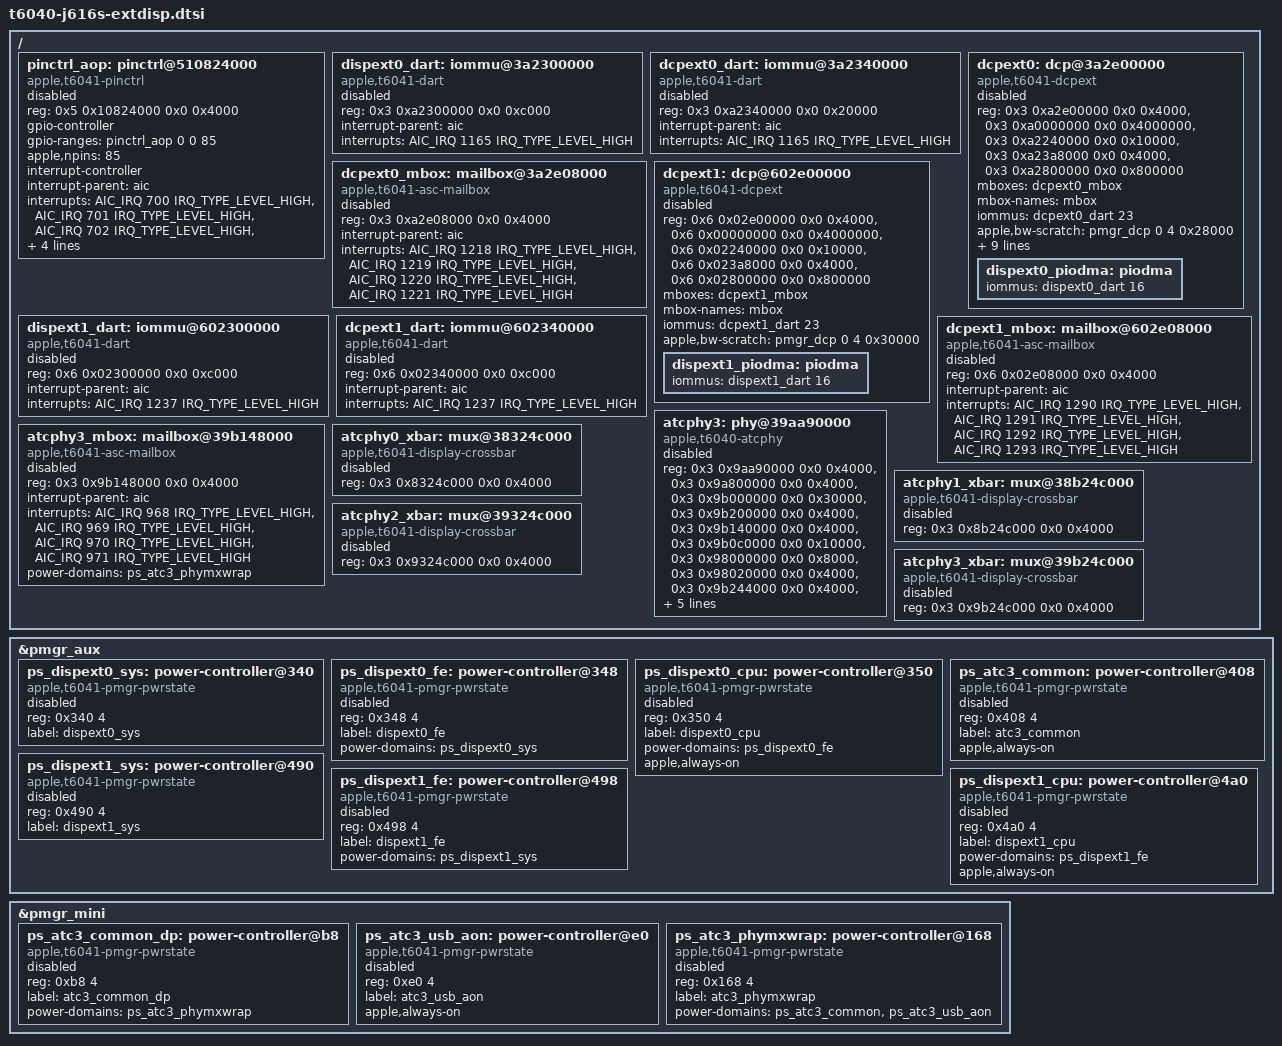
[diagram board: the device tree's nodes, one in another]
// SPDX-License-Identifier: GPL-2.0+ OR MIT
/*
 * External display resources of the J616s (T6041): HDMI and USB-C. Every
 * node is left disabled, so the booted hardware state is unchanged until
 * the kernel display gate (or a loader) enables the chain in order.
 *
 * Values come from this unit's ADT (macOS 25G83, this one unit); CPU
 * address = ADT address + 0x2_0000_0000. Path of the picture:
 *   HDMI:  dcpext0 -> atc3 display crossbar -> atcphy3 (fixed DP PHY, no
 *          USB controller) -> on-board DP-to-HDMI converter
 *   USB-C: dcpext1 -> atcN display crossbar -> atcphyN (DP alt mode)
 */

/ {
	pinctrl_aop: pinctrl@510824000 {
		compatible = "apple,t6041-pinctrl", "apple,t8103-pinctrl";
		reg = <0x5 0x10824000 0x0 0x4000>;

		gpio-controller;
		#gpio-cells = <2>;
		gpio-ranges = <&pinctrl_aop 0 0 85>;
		apple,npins = <85>;

		interrupt-controller;
		#interrupt-cells = <2>;
		interrupt-parent = <&aic>;
		interrupts = <AIC_IRQ 700 IRQ_TYPE_LEVEL_HIGH>,
			     <AIC_IRQ 701 IRQ_TYPE_LEVEL_HIGH>,
			     <AIC_IRQ 702 IRQ_TYPE_LEVEL_HIGH>,
			     <AIC_IRQ 703 IRQ_TYPE_LEVEL_HIGH>,
			     <AIC_IRQ 704 IRQ_TYPE_LEVEL_HIGH>,
			     <AIC_IRQ 705 IRQ_TYPE_LEVEL_HIGH>,
			     <AIC_IRQ 706 IRQ_TYPE_LEVEL_HIGH>;
		status = "disabled";
	};

	dispext0_dart: iommu@3a2300000 {
		compatible = "apple,t6041-dart", "apple,t8110-dart";
		reg = <0x3 0xa2300000 0x0 0xc000>;
		#iommu-cells = <1>;
		interrupt-parent = <&aic>;
		interrupts = <AIC_IRQ 1165 IRQ_TYPE_LEVEL_HIGH>;
		status = "disabled";
	};

	dcpext0_dart: iommu@3a2340000 {
		compatible = "apple,t6041-dart", "apple,t8110-dart";
		reg = <0x3 0xa2340000 0x0 0x20000>;
		#iommu-cells = <1>;
		interrupt-parent = <&aic>;
		interrupts = <AIC_IRQ 1165 IRQ_TYPE_LEVEL_HIGH>;
		status = "disabled";
	};

	dcpext0: dcp@3a2e00000 {
		compatible = "apple,t6041-dcpext", "apple,dcpext";
		reg = <0x3 0xa2e00000 0x0 0x4000>,
		      <0x3 0xa0000000 0x0 0x4000000>,
		      <0x3 0xa2240000 0x0 0x10000>,
		      <0x3 0xa23a8000 0x0 0x4000>,
		      <0x3 0xa2800000 0x0 0x800000>;
		reg-names = "coproc", "disp-0", "disp-1", "disp-2", "disp-3";
		mboxes = <&dcpext0_mbox>;
		mbox-names = "mbox";
		iommus = <&dcpext0_dart 23>;
		/* guessed: the internal DCP uses 0x20000, J700 DISPEXT0 is +0x8000 */
		apple,bw-scratch = <&pmgr_dcp 0 4 0x28000>;
		status = "disabled";

		dispext0_piodma: piodma {
			iommus = <&dispext0_dart 16>;
		};
	};

	dcpext0_mbox: mailbox@3a2e08000 {
		compatible = "apple,t6041-asc-mailbox", "apple,asc-mailbox-v4";
		reg = <0x3 0xa2e08000 0x0 0x4000>;
		interrupt-parent = <&aic>;
		interrupts = <AIC_IRQ 1218 IRQ_TYPE_LEVEL_HIGH>,
			     <AIC_IRQ 1219 IRQ_TYPE_LEVEL_HIGH>,
			     <AIC_IRQ 1220 IRQ_TYPE_LEVEL_HIGH>,
			     <AIC_IRQ 1221 IRQ_TYPE_LEVEL_HIGH>;
		interrupt-names = "send-empty", "send-not-empty",
				  "recv-empty", "recv-not-empty";
		#mbox-cells = <0>;
		status = "disabled";
	};

	dispext1_dart: iommu@602300000 {
		compatible = "apple,t6041-dart", "apple,t8110-dart";
		reg = <0x6 0x02300000 0x0 0xc000>;
		#iommu-cells = <1>;
		interrupt-parent = <&aic>;
		interrupts = <AIC_IRQ 1237 IRQ_TYPE_LEVEL_HIGH>;
		status = "disabled";
	};

	dcpext1_dart: iommu@602340000 {
		compatible = "apple,t6041-dart", "apple,t8110-dart";
		reg = <0x6 0x02340000 0x0 0xc000>;
		#iommu-cells = <1>;
		interrupt-parent = <&aic>;
		interrupts = <AIC_IRQ 1237 IRQ_TYPE_LEVEL_HIGH>;
		status = "disabled";
	};

	dcpext1: dcp@602e00000 {
		compatible = "apple,t6041-dcpext", "apple,dcpext";
		reg = <0x6 0x02e00000 0x0 0x4000>,
		      <0x6 0x00000000 0x0 0x4000000>,
		      <0x6 0x02240000 0x0 0x10000>,
		      <0x6 0x023a8000 0x0 0x4000>,
		      <0x6 0x02800000 0x0 0x800000>;
		reg-names = "coproc", "disp-0", "disp-1", "disp-2", "disp-3";
		mboxes = <&dcpext1_mbox>;
		mbox-names = "mbox";
		iommus = <&dcpext1_dart 23>;
		/* guessed, as dcpext0 */
		apple,bw-scratch = <&pmgr_dcp 0 4 0x30000>;
		status = "disabled";

		dispext1_piodma: piodma {
			iommus = <&dispext1_dart 16>;
		};
	};

	dcpext1_mbox: mailbox@602e08000 {
		compatible = "apple,t6041-asc-mailbox", "apple,asc-mailbox-v4";
		reg = <0x6 0x02e08000 0x0 0x4000>;
		interrupt-parent = <&aic>;
		interrupts = <AIC_IRQ 1290 IRQ_TYPE_LEVEL_HIGH>,
			     <AIC_IRQ 1291 IRQ_TYPE_LEVEL_HIGH>,
			     <AIC_IRQ 1292 IRQ_TYPE_LEVEL_HIGH>,
			     <AIC_IRQ 1293 IRQ_TYPE_LEVEL_HIGH>;
		interrupt-names = "send-empty", "send-not-empty",
				  "recv-empty", "recv-not-empty";
		#mbox-cells = <0>;
		status = "disabled";
	};

	/* ATC3: the HDMI converter's fixed DP PHY; no USB controller, no pipehandler. */
	atcphy3: phy@39aa90000 {
		compatible = "apple,t6040-atcphy";
		reg = <0x3 0x9aa90000 0x0 0x4000>,
		      <0x3 0x9a800000 0x0 0x4000>,
		      <0x3 0x9b000000 0x0 0x30000>,
		      <0x3 0x9b200000 0x0 0x4000>,
		      <0x3 0x9b140000 0x0 0x4000>,
		      <0x3 0x9b0c0000 0x0 0x10000>,
		      <0x3 0x98000000 0x0 0x8000>,
		      <0x3 0x98020000 0x0 0x4000>,
		      <0x3 0x9b244000 0x0 0x4000>,
		      <0x3 0x9b250000 0x0 0x4000>;
		reg-names = "bank0", "bank1", "core", "cfg", "cpu", "cpu-data",
			    "axi2af", "axi2af-lioa", "fabric", "common-cfg";
		#phy-cells = <1>;
		power-domains = <&ps_atc3_common_dp>;
		mboxes = <&atcphy3_mbox>;
		mbox-names = "phy-cpu";
		nonposted-mmio;
		status = "disabled";
	};

	atcphy3_mbox: mailbox@39b148000 {
		compatible = "apple,t6041-asc-mailbox", "apple,asc-mailbox-v4";
		reg = <0x3 0x9b148000 0x0 0x4000>;
		interrupt-parent = <&aic>;
		interrupts = <AIC_IRQ 968 IRQ_TYPE_LEVEL_HIGH>,
			     <AIC_IRQ 969 IRQ_TYPE_LEVEL_HIGH>,
			     <AIC_IRQ 970 IRQ_TYPE_LEVEL_HIGH>,
			     <AIC_IRQ 971 IRQ_TYPE_LEVEL_HIGH>;
		interrupt-names = "send-empty", "send-not-empty",
				  "recv-empty", "recv-not-empty";
		#mbox-cells = <0>;
		power-domains = <&ps_atc3_phymxwrap>;
		status = "disabled";
	};

	/* Display crossbars (ADT atcN-dpxbar, atc-dpxbar,t604x): no driver yet. */
	atcphy0_xbar: mux@38324c000 {
		compatible = "apple,t6041-display-crossbar";
		reg = <0x3 0x8324c000 0x0 0x4000>;
		#mux-control-cells = <1>;
		status = "disabled";
	};

	atcphy1_xbar: mux@38b24c000 {
		compatible = "apple,t6041-display-crossbar";
		reg = <0x3 0x8b24c000 0x0 0x4000>;
		#mux-control-cells = <1>;
		status = "disabled";
	};

	atcphy2_xbar: mux@39324c000 {
		compatible = "apple,t6041-display-crossbar";
		reg = <0x3 0x9324c000 0x0 0x4000>;
		#mux-control-cells = <1>;
		status = "disabled";
	};

	atcphy3_xbar: mux@39b24c000 {
		compatible = "apple,t6041-display-crossbar";
		reg = <0x3 0x9b24c000 0x0 0x4000>;
		#mux-control-cells = <1>;
		status = "disabled";
	};
};

/*
 * PMGR domains from the ADT device table (+16 offset, +19 block; block 0 =
 * pmgr_aux, block 3 = pmgr_mini; checked against the ATC0 nodes). Disabled
 * so the pwrstate driver does not touch them yet: DISPEXT0/1 run the
 * firmware iBoot loaded, and an always-on domain that happens to be off
 * would be powered on by the driver.
 */
&pmgr_aux {
	ps_dispext0_sys: power-controller@340 {
		compatible = "apple,t6041-pmgr-pwrstate", "apple,t8103-pmgr-pwrstate";
		reg = <0x340 4>;
		#power-domain-cells = <0>;
		#reset-cells = <0>;
		label = "dispext0_sys";
		status = "disabled";
	};

	ps_dispext0_fe: power-controller@348 {
		compatible = "apple,t6041-pmgr-pwrstate", "apple,t8103-pmgr-pwrstate";
		reg = <0x348 4>;
		#power-domain-cells = <0>;
		#reset-cells = <0>;
		label = "dispext0_fe";
		power-domains = <&ps_dispext0_sys>;
		status = "disabled";
	};

	ps_dispext0_cpu: power-controller@350 {
		compatible = "apple,t6041-pmgr-pwrstate", "apple,t8103-pmgr-pwrstate";
		reg = <0x350 4>;
		#power-domain-cells = <0>;
		#reset-cells = <0>;
		label = "dispext0_cpu";
		power-domains = <&ps_dispext0_fe>;
		apple,always-on;
		status = "disabled";
	};

	ps_atc3_common: power-controller@408 {
		compatible = "apple,t6041-pmgr-pwrstate", "apple,t8103-pmgr-pwrstate";
		reg = <0x408 4>;
		#power-domain-cells = <0>;
		#reset-cells = <0>;
		label = "atc3_common";
		apple,always-on;
		status = "disabled";
	};

	ps_dispext1_sys: power-controller@490 {
		compatible = "apple,t6041-pmgr-pwrstate", "apple,t8103-pmgr-pwrstate";
		reg = <0x490 4>;
		#power-domain-cells = <0>;
		#reset-cells = <0>;
		label = "dispext1_sys";
		status = "disabled";
	};

	ps_dispext1_fe: power-controller@498 {
		compatible = "apple,t6041-pmgr-pwrstate", "apple,t8103-pmgr-pwrstate";
		reg = <0x498 4>;
		#power-domain-cells = <0>;
		#reset-cells = <0>;
		label = "dispext1_fe";
		power-domains = <&ps_dispext1_sys>;
		status = "disabled";
	};

	ps_dispext1_cpu: power-controller@4a0 {
		compatible = "apple,t6041-pmgr-pwrstate", "apple,t8103-pmgr-pwrstate";
		reg = <0x4a0 4>;
		#power-domain-cells = <0>;
		#reset-cells = <0>;
		label = "dispext1_cpu";
		power-domains = <&ps_dispext1_fe>;
		apple,always-on;
		status = "disabled";
	};
};

&pmgr_mini {
	ps_atc3_common_dp: power-controller@b8 {
		compatible = "apple,t6041-pmgr-pwrstate", "apple,t8103-pmgr-pwrstate";
		reg = <0xb8 4>;
		#power-domain-cells = <0>;
		#reset-cells = <0>;
		label = "atc3_common_dp";
		power-domains = <&ps_atc3_phymxwrap>;
		status = "disabled";
	};

	ps_atc3_usb_aon: power-controller@e0 {
		compatible = "apple,t6041-pmgr-pwrstate", "apple,t8103-pmgr-pwrstate";
		reg = <0xe0 4>;
		#power-domain-cells = <0>;
		#reset-cells = <0>;
		label = "atc3_usb_aon";
		apple,always-on;
		status = "disabled";
	};

	ps_atc3_phymxwrap: power-controller@168 {
		compatible = "apple,t6041-pmgr-pwrstate", "apple,t8103-pmgr-pwrstate";
		reg = <0x168 4>;
		#power-domain-cells = <0>;
		#reset-cells = <0>;
		label = "atc3_phymxwrap";
		power-domains = <&ps_atc3_common>, <&ps_atc3_usb_aon>;
		status = "disabled";
	};
};

/*
 * HDMI port (disabled with dcpext0): converter power SMC gP0f/gP1a (as on
 * the M3 Pro J514s), HPD on AOP GPIO 0x24. The converter's reset (gP10),
 * force-dpfu (AOP GPIO 0x2a) and its I2C side channel (i2c8 0x08) are left
 * undescribed, as on the J514s.
 */
&dcpext0 {
	apple,connector-type = "HDMI-A";
	hdmi-hpd-gpios = <&pinctrl_aop 36 GPIO_ACTIVE_HIGH>;
	hdmi-pwren-gpios = <&smc_gpio 15 GPIO_ACTIVE_HIGH>;
	dp2hdmi-pwren-gpios = <&smc_gpio 26 GPIO_ACTIVE_HIGH>;
	phys = <&atcphy3 PHY_TYPE_DP>;
	phy-names = "dp-phy";
	mux-controls = <&atcphy3_xbar 0>;
	mux-control-names = "dp-xbar";
	mux-index = <0>;
	apple,dptx-phy = <3>;
};
